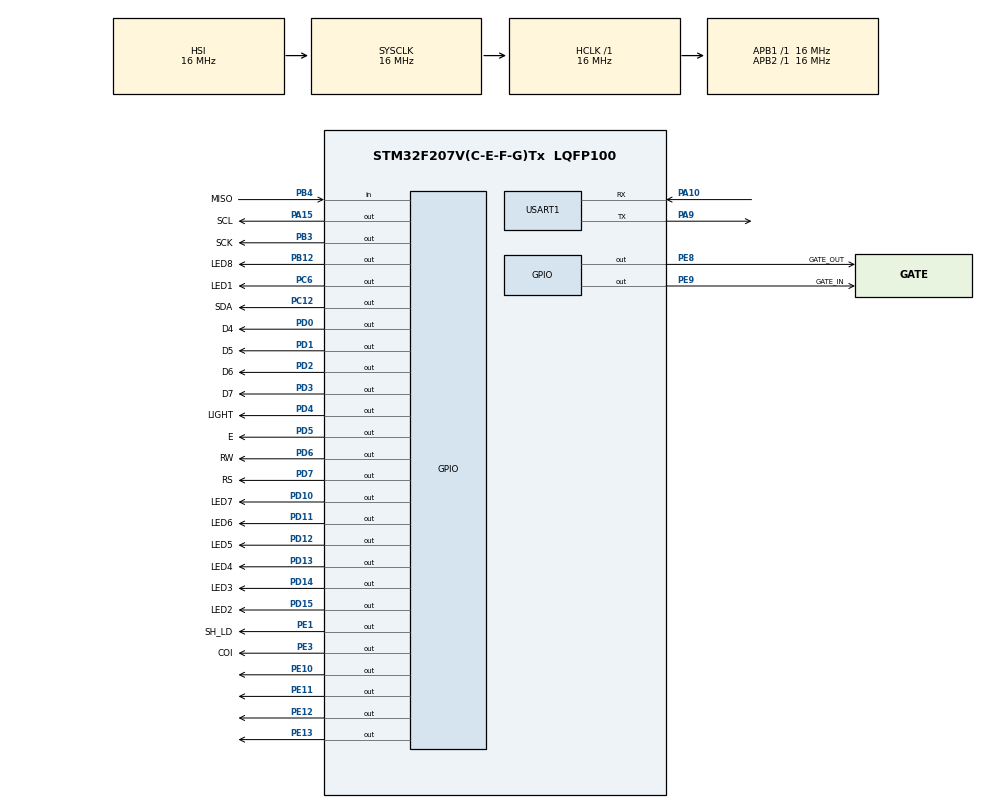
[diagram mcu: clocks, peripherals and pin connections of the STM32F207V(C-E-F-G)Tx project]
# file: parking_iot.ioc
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Mcu.Family=STM32F2
Mcu.Name=STM32F207V(C-E-F-G)Tx
Mcu.Package=LQFP100
NVIC.PriorityGroup=NVIC_PRIORITYGROUP_4
PA10.Mode=Asynchronous
PA10.Signal=USART1_RX
PA13.Mode=Serial_Wire
PA13.Signal=SYS_JTMS-SWDIO
PA14.Mode=Serial_Wire
PA14.Signal=SYS_JTCK-SWCLK
PA15.GPIO_Label=SCL
PA15.GPIO_ModeDefaultOutputPP=GPIO_MODE_OUTPUT_OD
PA15.GPIO_PuPd=GPIO_PULLUP
PA15.PinState=GPIO_PIN_SET
PA15.Signal=GPIO_Output
PA9.Mode=Asynchronous
PA9.Signal=USART1_TX
PB12.GPIO_Label=LED8
PB12.Signal=GPIO_Output
PB3.GPIO_Label=SCK
PB3.Signal=GPIO_Output
PB4.GPIO_Label=MISO
PB4.Signal=GPIO_Input
PC12.GPIO_Label=SDA
PC12.GPIO_ModeDefaultOutputPP=GPIO_MODE_OUTPUT_OD
PC12.GPIO_PuPd=GPIO_PULLUP
PC12.PinState=GPIO_PIN_SET
PC12.Signal=GPIO_Output
PC6.GPIO_Label=LED1
PC6.Signal=GPIO_Output
PD0.GPIO_Label=D4
PD0.Signal=GPIO_Output
PD1.GPIO_Label=D5
PD1.Signal=GPIO_Output
PD10.GPIO_Label=LED7
PD10.Signal=GPIO_Output
PD11.GPIO_Label=LED6
PD11.Signal=GPIO_Output
PD12.GPIO_Label=LED5
PD12.Signal=GPIO_Output
PD13.GPIO_Label=LED4
PD13.GPIO_PuPd=GPIO_PULLUP
PD13.Signal=GPIO_Output
PD14.GPIO_Label=LED3
PD14.Signal=GPIO_Output
PD15.GPIO_Label=LED2
PD15.Signal=GPIO_Output
PD2.GPIO_Label=D6
PD2.Signal=GPIO_Output
PD3.GPIO_Label=D7
PD3.Signal=GPIO_Output
PD4.GPIO_Label=LIGHT
PD4.PinState=GPIO_PIN_SET
PD4.Signal=GPIO_Output
PD5.GPIO_Label=E
PD5.Signal=GPIO_Output
PD6.GPIO_Label=RW
PD6.Signal=GPIO_Output
PD7.GPIO_Label=RS
PD7.Signal=GPIO_Output
PE1.GPIO_Label=SH_LD
PE1.Signal=GPIO_Output
PE10.Signal=GPIO_Output
PE11.Signal=GPIO_Output
PE12.Signal=GPIO_Output
PE13.Signal=GPIO_Output
PE3.GPIO_Label=COI
PE3.PinState=GPIO_PIN_SET
PE3.Signal=GPIO_Output
PE8.GPIO_Label=GATE_OUT
PE8.Signal=GPIO_Output
PE9.GPIO_Label=GATE_IN
PE9.Signal=GPIO_Output
ProjectManager.HeapSize=0x200
ProjectManager.StackSize=0x400
ProjectManager.TargetToolchain=STM32CubeIDE
RCC.48MHZClocksFreq_Value=48000000
RCC.AHBFreq_Value=16000000
RCC.APB1Freq_Value=16000000
RCC.APB2Freq_Value=16000000
RCC.CortexFreq_Value=16000000
RCC.HSE_VALUE=25000000
RCC.HSI_VALUE=16000000
RCC.LSE_VALUE=32768
RCC.SYSCLKFreq_VALUE=16000000
RCC.VCOOutputFreq_Value=192000000
TIM1.Period=0xFFFF
TIM1.Prescaler=15999
USART1.VirtualMode=VM_ASYNC
VP_TIM1_VS_ClockSourceINT.Mode=Internal
board=custom

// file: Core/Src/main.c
/* USER CODE BEGIN Header */
/**
  ******************************************************************************
  * @file           : main.c
  * @brief          : Main program body
  ******************************************************************************
  * @attention
  *
  * Copyright (c) 2026 STMicroelectronics.
  * All rights reserved.
  *
  * This software is licensed under terms that can be found in the LICENSE file
  * in the root directory of this software component.
  * If no LICENSE file comes with this software, it is provided AS-IS.
  *
  ******************************************************************************
  */
/* USER CODE END Header */
#include "main.h"

/* USER CODE BEGIN Includes */
#include "app_parking.h"
#include "eeprom_24c16.h"
#include "lcd.h"
#include "rs232_comm.h"
/* USER CODE END Includes */

TIM_HandleTypeDef htim1;

UART_HandleTypeDef huart1;

void SystemClock_Config(void);
static void MX_GPIO_Init(void);
static void MX_TIM1_Init(void);
static void MX_USART1_UART_Init(void);

int main(void)
{

  /* MCU Configuration--------------------------------------------------------*/

  /* Reset of all peripherals, Initializes the Flash interface and the Systick. */
  HAL_Init();

  /* Configure the system clock */
  SystemClock_Config();

  /* Initialize all configured peripherals */
  MX_GPIO_Init();
  MX_TIM1_Init();
  MX_USART1_UART_Init();
  /* USER CODE BEGIN 2 */
  lcd_init();
  eeprom_24c16_init();
  app_parking_init();
  rs232_init();
  /* USER CODE END 2 */

  /* Infinite loop */
  /* USER CODE BEGIN WHILE */
  while (1)
  {
	    app_parking_process();
    rs232_process();

    /* USER CODE END WHILE */

  }
}

void SystemClock_Config(void)
{
  RCC_OscInitTypeDef RCC_OscInitStruct = {0};
  RCC_ClkInitTypeDef RCC_ClkInitStruct = {0};

  /** Initializes the RCC Oscillators according to the specified parameters
  * in the RCC_OscInitTypeDef structure.
  */
  RCC_OscInitStruct.OscillatorType = RCC_OSCILLATORTYPE_HSI;
  RCC_OscInitStruct.HSIState = RCC_HSI_ON;
  RCC_OscInitStruct.HSICalibrationValue = RCC_HSICALIBRATION_DEFAULT;
  RCC_OscInitStruct.PLL.PLLState = RCC_PLL_NONE;
  if (HAL_RCC_OscConfig(&RCC_OscInitStruct) != HAL_OK)
  {
    Error_Handler();
  }

  /** Initializes the CPU, AHB and APB buses clocks
  */
  RCC_ClkInitStruct.ClockType = RCC_CLOCKTYPE_HCLK|RCC_CLOCKTYPE_SYSCLK
                              |RCC_CLOCKTYPE_PCLK1|RCC_CLOCKTYPE_PCLK2;
  RCC_ClkInitStruct.SYSCLKSource = RCC_SYSCLKSOURCE_HSI;
  RCC_ClkInitStruct.AHBCLKDivider = RCC_SYSCLK_DIV1;
  RCC_ClkInitStruct.APB1CLKDivider = RCC_HCLK_DIV1;
  RCC_ClkInitStruct.APB2CLKDivider = RCC_HCLK_DIV1;

  if (HAL_RCC_ClockConfig(&RCC_ClkInitStruct, FLASH_LATENCY_0) != HAL_OK)
  {
    Error_Handler();
  }
}

static void MX_TIM1_Init(void)
{

  TIM_ClockConfigTypeDef sClockSourceConfig = {0};
  TIM_MasterConfigTypeDef sMasterConfig = {0};

  htim1.Instance = TIM1;
  htim1.Init.Prescaler = 15999;
  htim1.Init.CounterMode = TIM_COUNTERMODE_UP;
  htim1.Init.Period = 0xFFFF;
  htim1.Init.ClockDivision = TIM_CLOCKDIVISION_DIV1;
  htim1.Init.RepetitionCounter = 0;
  htim1.Init.AutoReloadPreload = TIM_AUTORELOAD_PRELOAD_DISABLE;
  if (HAL_TIM_Base_Init(&htim1) != HAL_OK)
  {
    Error_Handler();
  }
  sClockSourceConfig.ClockSource = TIM_CLOCKSOURCE_INTERNAL;
  if (HAL_TIM_ConfigClockSource(&htim1, &sClockSourceConfig) != HAL_OK)
  {
    Error_Handler();
  }
  sMasterConfig.MasterOutputTrigger = TIM_TRGO_RESET;
  sMasterConfig.MasterSlaveMode = TIM_MASTERSLAVEMODE_DISABLE;
  if (HAL_TIMEx_MasterConfigSynchronization(&htim1, &sMasterConfig) != HAL_OK)
  {
    Error_Handler();
  }

}

static void MX_USART1_UART_Init(void)
{

  huart1.Instance = USART1;
  huart1.Init.BaudRate = 115200;
  huart1.Init.WordLength = UART_WORDLENGTH_8B;
  huart1.Init.StopBits = UART_STOPBITS_1;
  huart1.Init.Parity = UART_PARITY_NONE;
  huart1.Init.Mode = UART_MODE_TX_RX;
  huart1.Init.HwFlowCtl = UART_HWCONTROL_NONE;
  huart1.Init.OverSampling = UART_OVERSAMPLING_16;
  if (HAL_UART_Init(&huart1) != HAL_OK)
  {
    Error_Handler();
  }

}

static void MX_GPIO_Init(void)
{
  GPIO_InitTypeDef GPIO_InitStruct = {0};

  /* GPIO Ports Clock Enable */
  __HAL_RCC_GPIOE_CLK_ENABLE();
  __HAL_RCC_GPIOB_CLK_ENABLE();
  __HAL_RCC_GPIOD_CLK_ENABLE();
  __HAL_RCC_GPIOC_CLK_ENABLE();
  __HAL_RCC_GPIOA_CLK_ENABLE();

  /*Configure GPIO pin Output Level */
  HAL_GPIO_WritePin(COI_GPIO_Port, COI_Pin, GPIO_PIN_SET);

  /*Configure GPIO pin Output Level */
  HAL_GPIO_WritePin(GPIOE, GATE_OUT_Pin|GATE_IN_Pin|GPIO_PIN_10|GPIO_PIN_11
                          |GPIO_PIN_12|GPIO_PIN_13|SH_LD_Pin, GPIO_PIN_RESET);

  /*Configure GPIO pin Output Level */
  HAL_GPIO_WritePin(GPIOB, LED8_Pin|SCK_Pin, GPIO_PIN_RESET);

  /*Configure GPIO pin Output Level */
  HAL_GPIO_WritePin(GPIOD, LED7_Pin|LED6_Pin|LED5_Pin|LED4_Pin
                          |LED3_Pin|LED2_Pin|D4_Pin|D5_Pin
                          |D6_Pin|D7_Pin|E_Pin|RW_Pin
                          |RS_Pin, GPIO_PIN_RESET);

  /*Configure GPIO pin Output Level */
  HAL_GPIO_WritePin(LED1_GPIO_Port, LED1_Pin, GPIO_PIN_RESET);

  /*Configure GPIO pin Output Level */
  HAL_GPIO_WritePin(SCL_GPIO_Port, SCL_Pin, GPIO_PIN_SET);

  /*Configure GPIO pin Output Level */
  HAL_GPIO_WritePin(SDA_GPIO_Port, SDA_Pin, GPIO_PIN_SET);

  /*Configure GPIO pin Output Level */
  HAL_GPIO_WritePin(LIGHT_GPIO_Port, LIGHT_Pin, GPIO_PIN_SET);

  /*Configure GPIO pins : COI_Pin GATE_OUT_Pin GATE_IN_Pin PE10
                           PE11 PE12 PE13 SH_LD_Pin */
  GPIO_InitStruct.Pin = COI_Pin|GATE_OUT_Pin|GATE_IN_Pin|GPIO_PIN_10
                          |GPIO_PIN_11|GPIO_PIN_12|GPIO_PIN_13|SH_LD_Pin;
  GPIO_InitStruct.Mode = GPIO_MODE_OUTPUT_PP;
  GPIO_InitStruct.Pull = GPIO_NOPULL;
  GPIO_InitStruct.Speed = GPIO_SPEED_FREQ_LOW;
  HAL_GPIO_Init(GPIOE, &GPIO_InitStruct);

  /*Configure GPIO pins : LED8_Pin SCK_Pin */
  GPIO_InitStruct.Pin = LED8_Pin|SCK_Pin;
  GPIO_InitStruct.Mode = GPIO_MODE_OUTPUT_PP;
  GPIO_InitStruct.Pull = GPIO_NOPULL;
  GPIO_InitStruct.Speed = GPIO_SPEED_FREQ_LOW;
  HAL_GPIO_Init(GPIOB, &GPIO_InitStruct);

  /*Configure GPIO pins : LED7_Pin LED6_Pin LED5_Pin LED3_Pin
                           LED2_Pin D4_Pin D5_Pin D6_Pin
                           D7_Pin LIGHT_Pin E_Pin RW_Pin
                           RS_Pin */
  GPIO_InitStruct.Pin = LED7_Pin|LED6_Pin|LED5_Pin|LED3_Pin
                          |LED2_Pin|D4_Pin|D5_Pin|D6_Pin
                          |D7_Pin|LIGHT_Pin|E_Pin|RW_Pin
                          |RS_Pin;
  GPIO_InitStruct.Mode = GPIO_MODE_OUTPUT_PP;
  GPIO_InitStruct.Pull = GPIO_NOPULL;
  GPIO_InitStruct.Speed = GPIO_SPEED_FREQ_LOW;
  HAL_GPIO_Init(GPIOD, &GPIO_InitStruct);

  /*Configure GPIO pin : LED4_Pin */
  GPIO_InitStruct.Pin = LED4_Pin;
  GPIO_InitStruct.Mode = GPIO_MODE_OUTPUT_PP;
  GPIO_InitStruct.Pull = GPIO_PULLUP;
  GPIO_InitStruct.Speed = GPIO_SPEED_FREQ_LOW;
  HAL_GPIO_Init(LED4_GPIO_Port, &GPIO_InitStruct);

  /*Configure GPIO pin : LED1_Pin */
  GPIO_InitStruct.Pin = LED1_Pin;
  GPIO_InitStruct.Mode = GPIO_MODE_OUTPUT_PP;
  GPIO_InitStruct.Pull = GPIO_NOPULL;
  GPIO_InitStruct.Speed = GPIO_SPEED_FREQ_LOW;
  HAL_GPIO_Init(LED1_GPIO_Port, &GPIO_InitStruct);

  /*Configure GPIO pin : SCL_Pin */
  GPIO_InitStruct.Pin = SCL_Pin;
  GPIO_InitStruct.Mode = GPIO_MODE_OUTPUT_OD;
  GPIO_InitStruct.Pull = GPIO_PULLUP;
  GPIO_InitStruct.Speed = GPIO_SPEED_FREQ_LOW;
  HAL_GPIO_Init(SCL_GPIO_Port, &GPIO_InitStruct);

  /*Configure GPIO pin : SDA_Pin */
  GPIO_InitStruct.Pin = SDA_Pin;
  GPIO_InitStruct.Mode = GPIO_MODE_OUTPUT_OD;
  GPIO_InitStruct.Pull = GPIO_PULLUP;
  GPIO_InitStruct.Speed = GPIO_SPEED_FREQ_LOW;
  HAL_GPIO_Init(SDA_GPIO_Port, &GPIO_InitStruct);

  /*Configure GPIO pin : MISO_Pin */
  GPIO_InitStruct.Pin = MISO_Pin;
  GPIO_InitStruct.Mode = GPIO_MODE_INPUT;
  GPIO_InitStruct.Pull = GPIO_NOPULL;
  HAL_GPIO_Init(MISO_GPIO_Port, &GPIO_InitStruct);

  /* USER CODE BEGIN MX_GPIO_Init_2 */

  /*
   * Cam bien 4 o do xe:
   * DI.0 = PE13, DI.1 = PE12, DI.2 = PE11, DI.3 = PE10.
   * Tin hieu da di qua mach ngo vao 0...24 V cua ARM KIT 1.
   */
  GPIO_InitStruct.Pin = GPIO_PIN_8|GPIO_PIN_9|GPIO_PIN_10|GPIO_PIN_11|GPIO_PIN_12|GPIO_PIN_13;
  GPIO_InitStruct.Mode = GPIO_MODE_INPUT;
  GPIO_InitStruct.Pull = GPIO_PULLUP;
  HAL_GPIO_Init(GPIOE, &GPIO_InitStruct);

  /* USER CODE END MX_GPIO_Init_2 */
}

void Error_Handler(void)
{
  __disable_irq();
  while (1)
  {
  }
}
